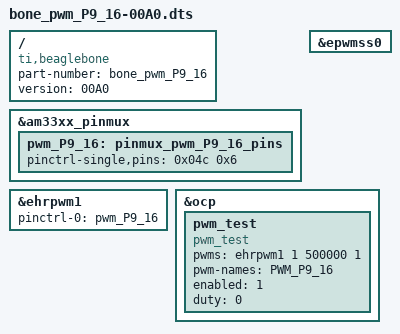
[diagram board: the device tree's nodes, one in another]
/*
 * Copyright (C) 2013 CircuitCo
 * Copyright (C) 2013 Texas Instruments
 *
 * This program is free software; you can redistribute it and/or modify
 * it under the terms of the GNU General Public License version 2 as
 * published by the Free Software Foundation.
 */
/dts-v1/;
/plugin/;

/ {
	compatible = "ti,beaglebone";

	/* identification */
	part-number = "bone_pwm_P9_16";
	version = "00A0";

	fragment@0 {
		target = <&am33xx_pinmux>;
		__overlay__ {
			pwm_P9_16: pinmux_pwm_P9_16_pins {
				pinctrl-single,pins = <0x04c  0x6>; /* P9_16 (ZCZ ball T14) | MODE 6 */
			};
		};
	};

	fragment@1 {
		target = <&epwmss0>;
		__overlay__ {
			status = "okay";
		};
	};

	fragment@2 {
		target = <&ehrpwm1>;
		__overlay__ {
			pinctrl-names	= "default";
			pinctrl-0	= <&pwm_P9_16>;
			status = "okay";
		};
	};

	fragment@3 {
		target = <&ocp>;
		__overlay__ {
			pwm_test {
				compatible	= "pwm_test";
				pwms 		= <&ehrpwm1 1 500000 1>;
				pwm-names 	= "PWM_P9_16";
				enabled		= <1>;
				duty		= <0>;
				status 		= "okay";
			};
		};
	};
};
